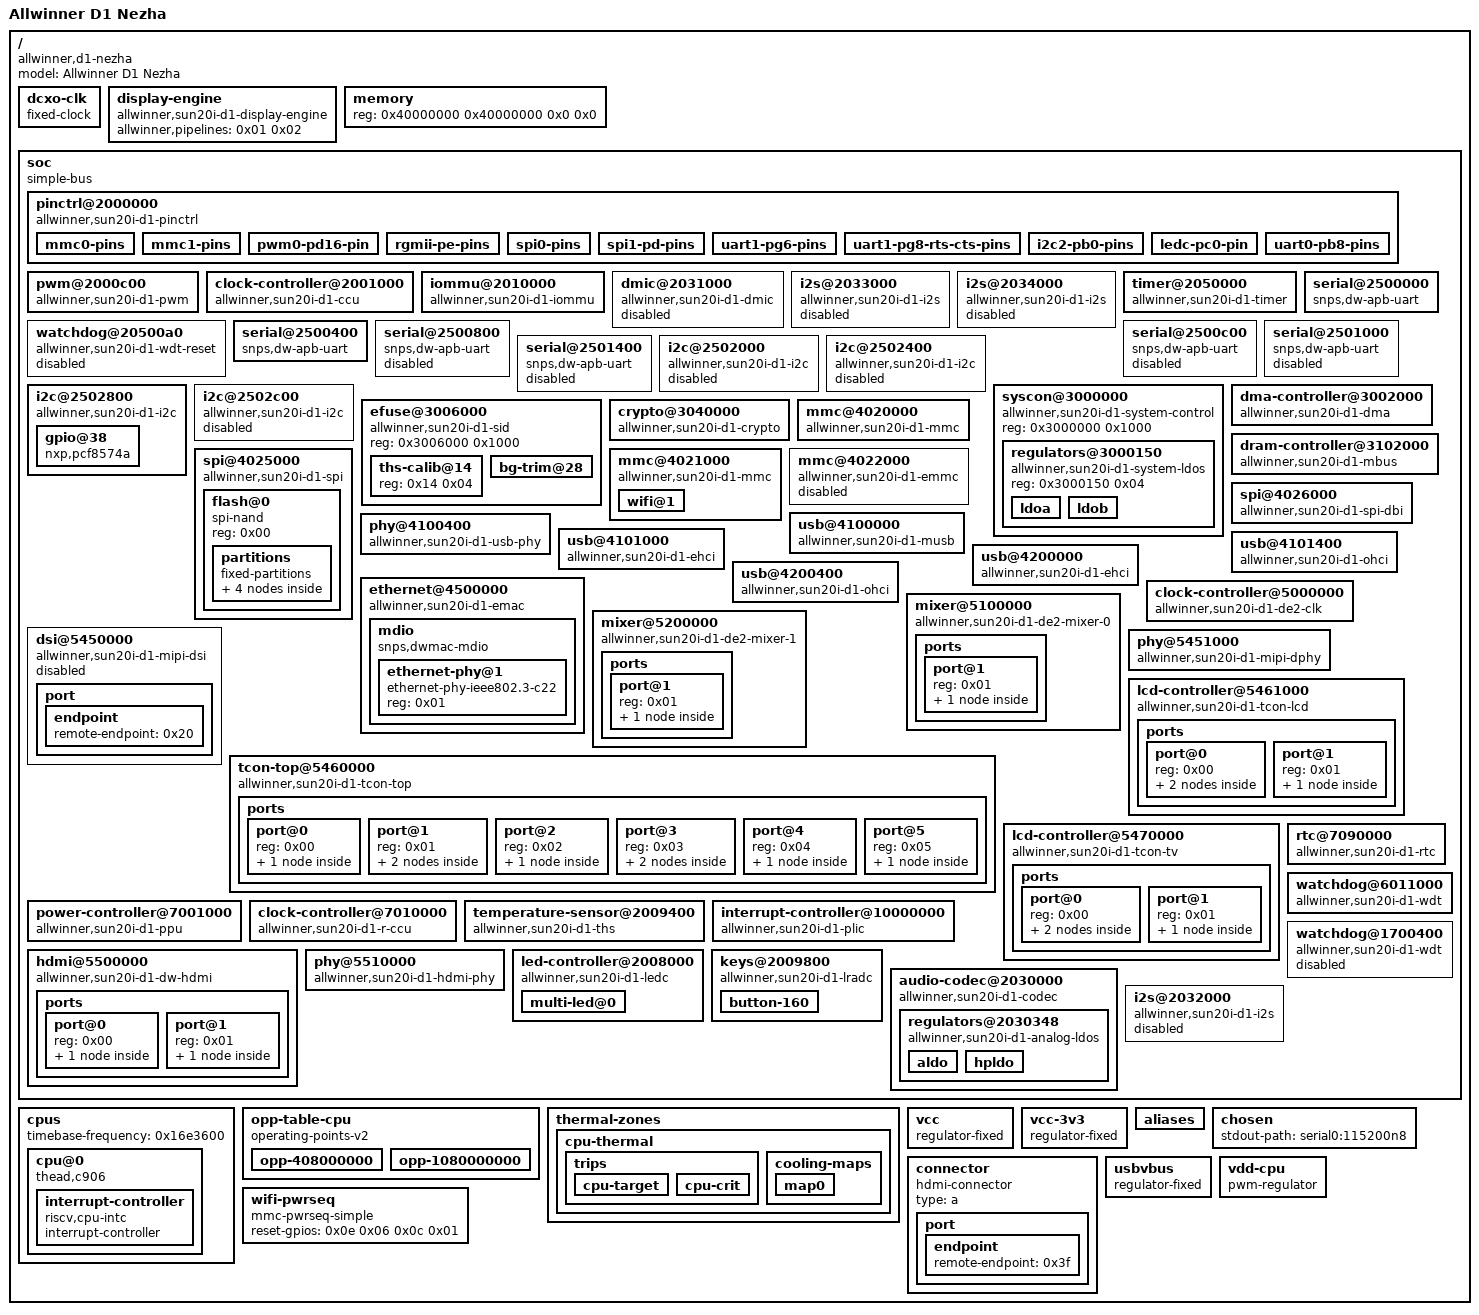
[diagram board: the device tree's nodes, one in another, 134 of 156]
/dts-v1/;

/ {
	#address-cells = <0x01>;
	#size-cells = <0x01>;
	model = "Allwinner D1 Nezha";
	compatible = "allwinner,d1-nezha\0allwinner,sun20i-d1";

	dcxo-clk {
		compatible = "fixed-clock";
		clock-output-names = "dcxo";
		#clock-cells = <0x00>;
		clock-frequency = <0x16e3600>;
		phandle = <0x05>;
	};

	display-engine {
		compatible = "allwinner,sun20i-d1-display-engine";
		allwinner,pipelines = <0x01 0x02>;
		status = "okay";
	};

        memory {
                device_type = "memory";
                reg = <0x40000000 0x40000000 0x0 0x0>;
        };


	soc {
		compatible = "simple-bus";
		ranges;
		dma-noncoherent;
		#address-cells = <0x01>;
		#size-cells = <0x01>;
		interrupt-parent = <0x03>;

		pinctrl@2000000 {
			compatible = "allwinner,sun20i-d1-pinctrl";
			reg = <0x2000000 0x800>;
			interrupts = <0x55 0x04 0x57 0x04 0x59 0x04 0x5b 0x04 0x5d 0x04 0x5f 0x04>;
			clocks = <0x04 0x18 0x05 0x06 0x00>;
			clock-names = "apb\0hosc\0losc";
			gpio-controller;
			interrupt-controller;
			#gpio-cells = <0x03>;
			#interrupt-cells = <0x03>;
			vcc-pb-supply = <0x07>;
			vcc-pc-supply = <0x07>;
			vcc-pd-supply = <0x07>;
			vcc-pe-supply = <0x07>;
			vcc-pf-supply = <0x07>;
			vcc-pg-supply = <0x07>;
			gpio-line-names = "\0\0\0\0\0\0\0\0\0\0\0\0\0\0\0\0\0\0\0\0\0\0\0\0\0\0\0\0\0\0\0\0pin5 [gpio2/twi2-sck]\0pin3 [gpio1/twi2-sda]\0\0pin38 [gpio24/i2s2-din]\0pin40 [gpio25/i2s2-dout]\0pin12 [gpio7/i2s-clk]\0pin35 [gpio22/i2s2-lrck]\0\0pin8 [gpio4/uart0-txd]\0pin10 [gpio5/uart0-rxd]\0\0\0pin15 [gpio9]\0\0\0\0\0\0\0\0\0\0\0\0\0\0\0\0\0\0\0\0\0\0pin31 [gpio21]\0\0\0\0\0\0\0\0\0\0\0\0\0\0\0\0\0\0\0\0\0\0\0\0\0\0\0\0\0\0\0\0\0\0\0\0\0\0\0\0\0pin24 [gpio16/spi1-ce0]\0pin23 [gpio15/spi1-clk]\0pin19 [gpio12/spi1-mosi]\0pin21 [gpio13/spi1-miso]\0pin27 [gpio18/spi1-hold]\0pin29 [gpio20/spi1-wp]\0\0\0\0\0\0\0pin7 [gpio3/pwm]";
			phandle = <0x0e>;

			mmc0-pins {
				pins = "PF0\0PF1\0PF2\0PF3\0PF4\0PF5";
				function = "mmc0";
				phandle = <0x0f>;
			};

			mmc1-pins {
				pins = "PG0\0PG1\0PG2\0PG3\0PG4\0PG5";
				function = "mmc1";
				phandle = <0x11>;
			};

			pwm0-pd16-pin {
				pins = "PD16";
				function = "pwm0";
				phandle = <0x08>;
			};

			rgmii-pe-pins {
				pins = "PE0\0PE1\0PE2\0PE3\0PE4\0PE5\0PE6\0PE7\0PE8\0PE9\0PE11\0PE12\0PE13\0PE14\0PE15";
				function = "emac";
				phandle = <0x18>;
			};

			spi0-pins {
				pins = "PC2\0PC3\0PC4\0PC5\0PC6\0PC7";
				function = "spi0";
				phandle = <0x12>;
			};

			spi1-pd-pins {
				pins = "PD10\0PD11\0PD12\0PD13\0PD14\0PD15";
				function = "spi1";
				phandle = <0x13>;
			};

			uart1-pg6-pins {
				pins = "PG6\0PG7";
				function = "uart1";
				phandle = <0x0b>;
			};

			uart1-pg8-rts-cts-pins {
				pins = "PG8\0PG9";
				function = "uart1";
				phandle = <0x0c>;
			};

			i2c2-pb0-pins {
				pins = "PB0\0PB1";
				function = "i2c2";
				phandle = <0x0d>;
			};

			ledc-pc0-pin {
				pins = "PC0";
				function = "ledc";
				phandle = <0x36>;
			};

			uart0-pb8-pins {
				pins = "PB8\0PB9";
				function = "uart0";
				phandle = <0x0a>;
			};
		};

		pwm@2000c00 {
			compatible = "allwinner,sun20i-d1-pwm";
			reg = <0x2000c00 0x400>;
			interrupts = <0x22 0x04>;
			clocks = <0x04 0x2d 0x05>;
			clock-names = "bus\0mod";
			resets = <0x04 0x0d>;
			status = "okay";
			#pwm-cells = <0x03>;
			pinctrl-0 = <0x08>;
			pinctrl-names = "default";
			phandle = <0x40>;
		};

		clock-controller@2001000 {
			compatible = "allwinner,sun20i-d1-ccu";
			reg = <0x2001000 0x1000>;
			clocks = <0x05 0x06 0x00 0x06 0x02>;
			clock-names = "hosc\0losc\0iosc";
			#clock-cells = <0x01>;
			#reset-cells = <0x01>;
			phandle = <0x04>;
		};

		iommu@2010000 {
			compatible = "allwinner,sun20i-d1-iommu";
			reg = <0x2010000 0x10000>;
			interrupts = <0x50 0x04>;
			clocks = <0x04 0x2e>;
			#iommu-cells = <0x01>;
			phandle = <0x1b>;
		};

		dmic@2031000 {
			compatible = "allwinner,sun20i-d1-dmic\0allwinner,sun50i-h6-dmic";
			reg = <0x2031000 0x400>;
			interrupts = <0x28 0x04>;
			clocks = <0x04 0x5d 0x04 0x5c>;
			clock-names = "bus\0mod";
			resets = <0x04 0x26>;
			dmas = <0x09 0x08>;
			dma-names = "rx";
			status = "disabled";
			#sound-dai-cells = <0x00>;
		};

		i2s@2033000 {
			compatible = "allwinner,sun20i-d1-i2s\0allwinner,sun50i-r329-i2s";
			reg = <0x2033000 0x1000>;
			interrupts = <0x2b 0x04>;
			clocks = <0x04 0x57 0x04 0x53>;
			clock-names = "apb\0mod";
			resets = <0x04 0x23>;
			dmas = <0x09 0x04 0x09 0x04>;
			dma-names = "rx\0tx";
			status = "disabled";
			#sound-dai-cells = <0x00>;
		};

		i2s@2034000 {
			compatible = "allwinner,sun20i-d1-i2s\0allwinner,sun50i-r329-i2s";
			reg = <0x2034000 0x1000>;
			interrupts = <0x2c 0x04>;
			clocks = <0x04 0x58 0x04 0x54>;
			clock-names = "apb\0mod";
			resets = <0x04 0x24>;
			dmas = <0x09 0x05 0x09 0x05>;
			dma-names = "rx\0tx";
			status = "disabled";
			#sound-dai-cells = <0x00>;
		};

		timer@2050000 {
			compatible = "allwinner,sun20i-d1-timer\0allwinner,sun8i-a23-timer";
			reg = <0x2050000 0xa0>;
			interrupts = <0x4b 0x04 0x4c 0x04>;
			clocks = <0x05>;
		};

		watchdog@20500a0 {
			compatible = "allwinner,sun20i-d1-wdt-reset\0allwinner,sun20i-d1-wdt";
			reg = <0x20500a0 0x20>;
			interrupts = <0x4f 0x04>;
			clocks = <0x05 0x06 0x00>;
			clock-names = "hosc\0losc";
			status = "reserved";
		};

		serial@2500000 {
			compatible = "snps,dw-apb-uart";
			reg = <0x2500000 0x400>;
			reg-io-width = <0x04>;
			reg-shift = <0x02>;
			interrupts = <0x12 0x04>;
			clocks = <0x04 0x3e>;
			clock-names = "apb";
			resets = <0x04 0x12>;
			dmas = <0x09 0x0e 0x09 0x0e>;
			dma-names = "rx\0tx";
			status = "okay";
			pinctrl-0 = <0x0a>;
			pinctrl-names = "default";
		};

		serial@2500400 {
			compatible = "snps,dw-apb-uart";
			reg = <0x2500400 0x400>;
			reg-io-width = <0x04>;
			reg-shift = <0x02>;
			interrupts = <0x13 0x04>;
			clocks = <0x04 0x3f>;
			clock-names = "apb";
			resets = <0x04 0x13>;
			dmas = <0x09 0x0f 0x09 0x0f>;
			dma-names = "rx\0tx";
			status = "okay";
			uart-has-rtscts;
			pinctrl-0 = <0x0b 0x0c>;
			pinctrl-names = "default";
		};

		serial@2500800 {
			compatible = "snps,dw-apb-uart";
			reg = <0x2500800 0x400>;
			reg-io-width = <0x04>;
			reg-shift = <0x02>;
			interrupts = <0x14 0x04>;
			clocks = <0x04 0x40>;
			resets = <0x04 0x14>;
			dmas = <0x09 0x10 0x09 0x10>;
			dma-names = "rx\0tx";
			status = "disabled";
		};

		serial@2500c00 {
			compatible = "snps,dw-apb-uart";
			reg = <0x2500c00 0x400>;
			reg-io-width = <0x04>;
			reg-shift = <0x02>;
			interrupts = <0x15 0x04>;
			clocks = <0x04 0x41>;
			resets = <0x04 0x15>;
			dmas = <0x09 0x11 0x09 0x11>;
			dma-names = "rx\0tx";
			status = "disabled";
		};

		serial@2501000 {
			compatible = "snps,dw-apb-uart";
			reg = <0x2501000 0x400>;
			reg-io-width = <0x04>;
			reg-shift = <0x02>;
			interrupts = <0x16 0x04>;
			clocks = <0x04 0x42>;
			resets = <0x04 0x16>;
			dmas = <0x09 0x12 0x09 0x12>;
			dma-names = "rx\0tx";
			status = "disabled";
		};

		serial@2501400 {
			compatible = "snps,dw-apb-uart";
			reg = <0x2501400 0x400>;
			reg-io-width = <0x04>;
			reg-shift = <0x02>;
			interrupts = <0x17 0x04>;
			clocks = <0x04 0x43>;
			resets = <0x04 0x17>;
			dmas = <0x09 0x13 0x09 0x13>;
			dma-names = "rx\0tx";
			status = "disabled";
		};

		i2c@2502000 {
			compatible = "allwinner,sun20i-d1-i2c\0allwinner,sun8i-v536-i2c\0allwinner,sun6i-a31-i2c";
			reg = <0x2502000 0x400>;
			interrupts = <0x19 0x04>;
			clocks = <0x04 0x44>;
			resets = <0x04 0x18>;
			dmas = <0x09 0x2b 0x09 0x2b>;
			dma-names = "rx\0tx";
			status = "disabled";
			#address-cells = <0x01>;
			#size-cells = <0x00>;
		};

		i2c@2502400 {
			compatible = "allwinner,sun20i-d1-i2c\0allwinner,sun8i-v536-i2c\0allwinner,sun6i-a31-i2c";
			reg = <0x2502400 0x400>;
			interrupts = <0x1a 0x04>;
			clocks = <0x04 0x45>;
			resets = <0x04 0x19>;
			dmas = <0x09 0x2c 0x09 0x2c>;
			dma-names = "rx\0tx";
			status = "disabled";
			#address-cells = <0x01>;
			#size-cells = <0x00>;
		};

		i2c@2502800 {
			compatible = "allwinner,sun20i-d1-i2c\0allwinner,sun8i-v536-i2c\0allwinner,sun6i-a31-i2c";
			reg = <0x2502800 0x400>;
			interrupts = <0x1b 0x04>;
			clocks = <0x04 0x46>;
			resets = <0x04 0x1a>;
			dmas = <0x09 0x2d 0x09 0x2d>;
			dma-names = "rx\0tx";
			status = "okay";
			#address-cells = <0x01>;
			#size-cells = <0x00>;
			pinctrl-0 = <0x0d>;
			pinctrl-names = "default";

			gpio@38 {
				compatible = "nxp,pcf8574a";
				reg = <0x38>;
				interrupt-parent = <0x0e>;
				interrupts = <0x01 0x02 0x08>;
				interrupt-controller;
				gpio-controller;
				#gpio-cells = <0x02>;
				#interrupt-cells = <0x02>;
				gpio-line-names = "pin13 [gpio8]\0pin16 [gpio10]\0pin18 [gpio11]\0pin26 [gpio17]\0pin22 [gpio14]\0pin28 [gpio19]\0pin37 [gpio23]\0pin11 [gpio6]";
			};
		};

		i2c@2502c00 {
			compatible = "allwinner,sun20i-d1-i2c\0allwinner,sun8i-v536-i2c\0allwinner,sun6i-a31-i2c";
			reg = <0x2502c00 0x400>;
			interrupts = <0x1c 0x04>;
			clocks = <0x04 0x47>;
			resets = <0x04 0x1b>;
			dmas = <0x09 0x2e 0x09 0x2e>;
			dma-names = "rx\0tx";
			status = "disabled";
			#address-cells = <0x01>;
			#size-cells = <0x00>;
		};

		syscon@3000000 {
			compatible = "allwinner,sun20i-d1-system-control";
			reg = <0x3000000 0x1000>;
			ranges;
			#address-cells = <0x01>;
			#size-cells = <0x01>;
			phandle = <0x17>;

			regulators@3000150 {
				compatible = "allwinner,sun20i-d1-system-ldos";
				reg = <0x3000150 0x04>;

				ldoa {
					regulator-always-on;
					regulator-min-microvolt = <0x1b7740>;
					regulator-max-microvolt = <0x1b7740>;
					ldo-in-supply = <0x07>;
					phandle = <0x33>;
				};

				ldob {
				};
			};
		};

		dma-controller@3002000 {
			compatible = "allwinner,sun20i-d1-dma";
			reg = <0x3002000 0x1000>;
			interrupts = <0x42 0x04>;
			clocks = <0x04 0x25 0x04 0x30>;
			clock-names = "bus\0mbus";
			resets = <0x04 0x06>;
			dma-channels = <0x10>;
			dma-requests = <0x30>;
			#dma-cells = <0x01>;
			phandle = <0x09>;
		};

		efuse@3006000 {
			compatible = "allwinner,sun20i-d1-sid";
			reg = <0x3006000 0x1000>;
			#address-cells = <0x01>;
			#size-cells = <0x01>;

			ths-calib@14 {
				reg = <0x14 0x04>;
				phandle = <0x30>;
			};

			bg-trim@28 {
				reg = <0x28 0x04>;
				bits = <0x10 0x08>;
				phandle = <0x39>;
			};
		};

		crypto@3040000 {
			compatible = "allwinner,sun20i-d1-crypto";
			reg = <0x3040000 0x800>;
			interrupts = <0x44 0x04>;
			clocks = <0x04 0x22 0x04 0x21 0x04 0x32 0x06 0x02>;
			clock-names = "bus\0mod\0ram\0trng";
			resets = <0x04 0x04>;
		};

		dram-controller@3102000 {
			compatible = "allwinner,sun20i-d1-mbus";
			reg = <0x3102000 0x1000 0x3103000 0x1000>;
			reg-names = "mbus\0dram";
			interrupts = <0x3b 0x04>;
			clocks = <0x04 0x1a 0x04 0x2f 0x04 0x37>;
			clock-names = "mbus\0dram\0bus";
			dma-ranges = <0x00 0x40000000 0x80000000>;
			#address-cells = <0x01>;
			#size-cells = <0x01>;
			#interconnect-cells = <0x01>;
		};

		mmc@4020000 {
			compatible = "allwinner,sun20i-d1-mmc";
			reg = <0x4020000 0x1000>;
			interrupts = <0x38 0x04>;
			clocks = <0x04 0x3b 0x04 0x38>;
			clock-names = "ahb\0mmc";
			resets = <0x04 0x0f>;
			reset-names = "ahb";
			cap-sd-highspeed;
			max-frequency = <0x8f0d180>;
			no-mmc;
			status = "okay";
			#address-cells = <0x01>;
			#size-cells = <0x00>;
			bus-width = <0x04>;
			cd-gpios = <0x0e 0x05 0x06 0x00>;
			disable-wp;
			vmmc-supply = <0x07>;
			vqmmc-supply = <0x07>;
			pinctrl-0 = <0x0f>;
			pinctrl-names = "default";
		};

		mmc@4021000 {
			compatible = "allwinner,sun20i-d1-mmc";
			reg = <0x4021000 0x1000>;
			interrupts = <0x39 0x04>;
			clocks = <0x04 0x3c 0x04 0x39>;
			clock-names = "ahb\0mmc";
			resets = <0x04 0x10>;
			reset-names = "ahb";
			cap-sd-highspeed;
			max-frequency = <0x8f0d180>;
			no-mmc;
			status = "okay";
			#address-cells = <0x01>;
			#size-cells = <0x00>;
			bus-width = <0x04>;
			mmc-pwrseq = <0x10>;
			non-removable;
			vmmc-supply = <0x07>;
			vqmmc-supply = <0x07>;
			pinctrl-0 = <0x11>;
			pinctrl-names = "default";

			wifi@1 {
				reg = <0x01>;
				interrupt-parent = <0x0e>;
				interrupts = <0x06 0x0a 0x08>;
				interrupt-names = "host-wake";
			};
		};

		mmc@4022000 {
			compatible = "allwinner,sun20i-d1-emmc\0allwinner,sun50i-a100-emmc";
			reg = <0x4022000 0x1000>;
			interrupts = <0x3a 0x04>;
			clocks = <0x04 0x3d 0x04 0x3a>;
			clock-names = "ahb\0mmc";
			resets = <0x04 0x11>;
			reset-names = "ahb";
			cap-mmc-highspeed;
			max-frequency = <0x8f0d180>;
			mmc-ddr-1_8v;
			mmc-ddr-3_3v;
			no-sd;
			no-sdio;
			status = "disabled";
			#address-cells = <0x01>;
			#size-cells = <0x00>;
		};

		spi@4025000 {
			compatible = "allwinner,sun20i-d1-spi\0allwinner,sun50i-r329-spi";
			reg = <0x4025000 0x1000>;
			interrupts = <0x1f 0x04>;
			clocks = <0x04 0x4a 0x04 0x48>;
			clock-names = "ahb\0mod";
			resets = <0x04 0x1c>;
			dmas = <0x09 0x16 0x09 0x16>;
			dma-names = "rx\0tx";
			num-cs = <0x01>;
			status = "okay";
			#address-cells = <0x01>;
			#size-cells = <0x00>;
			pinctrl-0 = <0x12>;
			pinctrl-names = "default";

			flash@0 {
				compatible = "spi-nand";
				reg = <0x00>;

				partitions {
					compatible = "fixed-partitions";
					#address-cells = <0x01>;
					#size-cells = <0x01>;

					partition@0 {
						label = "boot0";
						reg = <0x00 0x100000>;
					};

					partition@100000 {
						label = "uboot";
						reg = <0x100000 0x300000>;
					};

					partition@400000 {
						label = "secure_storage";
						reg = <0x400000 0x100000>;
					};

					partition@500000 {
						label = "sys";
						reg = <0x500000 0xfb00000>;
					};
				};
			};
		};

		spi@4026000 {
			compatible = "allwinner,sun20i-d1-spi-dbi\0allwinner,sun50i-r329-spi-dbi\0allwinner,sun50i-r329-spi";
			reg = <0x4026000 0x1000>;
			interrupts = <0x20 0x04>;
			clocks = <0x04 0x4b 0x04 0x49>;
			clock-names = "ahb\0mod";
			resets = <0x04 0x1d>;
			dmas = <0x09 0x17 0x09 0x17>;
			dma-names = "rx\0tx";
			num-cs = <0x01>;
			status = "okay";
			#address-cells = <0x01>;
			#size-cells = <0x00>;
			pinctrl-0 = <0x13>;
			pinctrl-names = "default";
		};

		usb@4100000 {
			compatible = "allwinner,sun20i-d1-musb\0allwinner,sun8i-a33-musb";
			reg = <0x4100000 0x400>;
			interrupts = <0x2d 0x04>;
			interrupt-names = "mc";
			clocks = <0x04 0x67>;
			resets = <0x04 0x2e>;
			extcon = <0x14 0x00>;
			phys = <0x14 0x00>;
			phy-names = "usb";
			status = "okay";
			dr_mode = "otg";
		};

		phy@4100400 {
			compatible = "allwinner,sun20i-d1-usb-phy";
			reg = <0x4100400 0x100 0x4101800 0x100 0x4200800 0x100>;
			reg-names = "phy_ctrl\0pmu0\0pmu1";
			clocks = <0x05 0x05>;
			clock-names = "usb0_phy\0usb1_phy";
			resets = <0x04 0x28 0x04 0x29>;
			reset-names = "usb0_reset\0usb1_reset";
			status = "okay";
			#phy-cells = <0x01>;
			usb0_id_det-gpios = <0x0e 0x03 0x15 0x00>;
			usb0_vbus_det-gpios = <0x0e 0x03 0x14 0x00>;
			usb0_vbus-supply = <0x15>;
			usb1_vbus-supply = <0x16>;
			phandle = <0x14>;
		};

		usb@4101000 {
			compatible = "allwinner,sun20i-d1-ehci\0generic-ehci";
			reg = <0x4101000 0x100>;
			interrupts = <0x2e 0x04>;
			clocks = <0x04 0x63 0x04 0x65 0x04 0x61>;
			resets = <0x04 0x2a 0x04 0x2c>;
			phys = <0x14 0x00>;
			phy-names = "usb";
			status = "okay";
		};

		usb@4101400 {
			compatible = "allwinner,sun20i-d1-ohci\0generic-ohci";
			reg = <0x4101400 0x100>;
			interrupts = <0x2f 0x04>;
			clocks = <0x04 0x63 0x04 0x61>;
			resets = <0x04 0x2a>;
			phys = <0x14 0x00>;
			phy-names = "usb";
			status = "okay";
		};

		usb@4200000 {
			compatible = "allwinner,sun20i-d1-ehci\0generic-ehci";
			reg = <0x4200000 0x100>;
			interrupts = <0x31 0x04>;
			clocks = <0x04 0x64 0x04 0x66 0x04 0x62>;
			resets = <0x04 0x2b 0x04 0x2d>;
			phys = <0x14 0x01>;
			phy-names = "usb";
			status = "okay";
		};

		usb@4200400 {
			compatible = "allwinner,sun20i-d1-ohci\0generic-ohci";
			reg = <0x4200400 0x100>;
			interrupts = <0x32 0x04>;
			clocks = <0x04 0x64 0x04 0x62>;
			resets = <0x04 0x2b>;
			phys = <0x14 0x01>;
			phy-names = "usb";
			status = "okay";
		};

		ethernet@4500000 {
			compatible = "allwinner,sun20i-d1-emac\0allwinner,sun50i-a64-emac";
			reg = <0x4500000 0x10000>;
			interrupts = <0x3e 0x04>;
			interrupt-names = "macirq";
			clocks = <0x04 0x4d>;
			clock-names = "stmmaceth";
			resets = <0x04 0x1e>;
			reset-names = "stmmaceth";
			syscon = <0x17>;
			status = "okay";
			pinctrl-0 = <0x18>;
			pinctrl-names = "default";
			phy-handle = <0x19>;
			phy-mode = "rgmii-id";
			phy-supply = <0x07>;

			mdio {
				compatible = "snps,dwmac-mdio";
				#address-cells = <0x01>;
				#size-cells = <0x00>;

				ethernet-phy@1 {
					compatible = "ethernet-phy-ieee802.3-c22";
					reg = <0x01>;
					phandle = <0x19>;
				};
			};
		};

		clock-controller@5000000 {
			compatible = "allwinner,sun20i-d1-de2-clk\0allwinner,sun50i-h5-de2-clk";
			reg = <0x5000000 0x10000>;
			clocks = <0x04 0x1c 0x04 0x1b>;
			clock-names = "bus\0mod";
			resets = <0x04 0x01>;
			#clock-cells = <0x01>;
			#reset-cells = <0x01>;
			phandle = <0x1a>;
		};

		mixer@5100000 {
			compatible = "allwinner,sun20i-d1-de2-mixer-0";
			reg = <0x5100000 0x100000>;
			clocks = <0x1a 0x00 0x1a 0x06>;
			clock-names = "bus\0mod";
			resets = <0x1a 0x00>;
			iommus = <0x1b 0x02>;
			phandle = <0x01>;

			ports {
				#address-cells = <0x01>;
				#size-cells = <0x00>;

				port@1 {
					reg = <0x01>;

					endpoint {
						remote-endpoint = <0x1c>;
						phandle = <0x21>;
					};
				};
			};
		};

		mixer@5200000 {
			compatible = "allwinner,sun20i-d1-de2-mixer-1";
			reg = <0x5200000 0x100000>;
			clocks = <0x1a 0x01 0x1a 0x07>;
			clock-names = "bus\0mod";
			resets = <0x1a 0x01>;
			iommus = <0x1b 0x02>;
			phandle = <0x02>;

			ports {
				#address-cells = <0x01>;
				#size-cells = <0x00>;

				port@1 {
					reg = <0x01>;

					endpoint {
						remote-endpoint = <0x1d>;
						phandle = <0x24>;
					};
				};
			};
		};

		dsi@5450000 {
			compatible = "allwinner,sun20i-d1-mipi-dsi\0allwinner,sun50i-a100-mipi-dsi";
			reg = <0x5450000 0x1000>;
			interrupts = <0x6c 0x04>;
			clocks = <0x04 0x6f 0x1e 0x02>;
			clock-names = "bus\0mod";
			resets = <0x04 0x33>;
			phys = <0x1f>;
			phy-names = "dphy";
			status = "disabled";

			port {

				endpoint {
					remote-endpoint = <0x20>;
					phandle = <0x2b>;
				};
			};
		};

		phy@5451000 {
			compatible = "allwinner,sun20i-d1-mipi-dphy\0allwinner,sun50i-a100-mipi-dphy";
			reg = <0x5451000 0x1000>;
			interrupts = <0x6c 0x04>;
			clocks = <0x04 0x6f 0x04 0x6e>;
			clock-names = "bus\0mod";
			resets = <0x04 0x33>;
			#phy-cells = <0x00>;
			phandle = <0x1f>;
		};

		tcon-top@5460000 {
			compatible = "allwinner,sun20i-d1-tcon-top";
			reg = <0x5460000 0x1000>;
			clocks = <0x04 0x69 0x04 0x72 0x04 0x74 0x04 0x70>;
			clock-names = "bus\0tcon-tv0\0tve0\0dsi";
			clock-output-names = "tcon-top-tv0\0tcon-top-dsi";
			resets = <0x04 0x30>;
			#clock-cells = <0x01>;
			phandle = <0x1e>;

			ports {
				#address-cells = <0x01>;
				#size-cells = <0x00>;

				port@0 {
					reg = <0x00>;

					endpoint {
						remote-endpoint = <0x21>;
						phandle = <0x1c>;
					};
				};

				port@1 {
					reg = <0x01>;
					#address-cells = <0x01>;
					#size-cells = <0x00>;

					endpoint@0 {
						reg = <0x00>;
						remote-endpoint = <0x22>;
						phandle = <0x29>;
					};

					endpoint@2 {
						reg = <0x02>;
						remote-endpoint = <0x23>;
						phandle = <0x2c>;
					};
				};

				port@2 {
					reg = <0x02>;
					#address-cells = <0x01>;
					#size-cells = <0x00>;

					endpoint@1 {
						reg = <0x01>;
						remote-endpoint = <0x24>;
						phandle = <0x1d>;
					};
				};

				port@3 {
					reg = <0x03>;
					#address-cells = <0x01>;
					#size-cells = <0x00>;

					endpoint@0 {
						reg = <0x00>;
						remote-endpoint = <0x25>;
						phandle = <0x2a>;
					};

					endpoint@2 {
						reg = <0x02>;
						remote-endpoint = <0x26>;
						phandle = <0x2d>;
					};
				};

				port@4 {
					reg = <0x04>;

					endpoint {
						remote-endpoint = <0x27>;
						phandle = <0x2e>;
					};
				};

				port@5 {
					reg = <0x05>;

					endpoint {
						remote-endpoint = <0x28>;
						phandle = <0x34>;
					};
				};
			};
		};

		lcd-controller@5461000 {
			compatible = "allwinner,sun20i-d1-tcon-lcd";
			reg = <0x5461000 0x1000>;
			interrupts = <0x6a 0x04>;
			clocks = <0x04 0x71 0x04 0x70>;
			clock-names = "ahb\0tcon-ch0";
			clock-output-names = "tcon-pixel-clock";
			resets = <0x04 0x34 0x04 0x36>;
			reset-names = "lcd\0lvds";
			phys = <0x1f>;
			phy-names = "lvds0";
			#clock-cells = <0x00>;

			ports {
				#address-cells = <0x01>;
				#size-cells = <0x00>;

				port@0 {
					reg = <0x00>;
					#address-cells = <0x01>;
					#size-cells = <0x00>;

					endpoint@0 {
						reg = <0x00>;
						remote-endpoint = <0x29>;
						phandle = <0x22>;
					};

					endpoint@1 {
						reg = <0x01>;
						remote-endpoint = <0x2a>;
						phandle = <0x25>;
					};
				};

				port@1 {
					reg = <0x01>;
					#address-cells = <0x01>;
					#size-cells = <0x00>;

					endpoint@1 {
						reg = <0x01>;
						remote-endpoint = <0x2b>;
						phandle = <0x20>;
					};
				};
			};
		};

		lcd-controller@5470000 {
			compatible = "allwinner,sun20i-d1-tcon-tv";
			reg = <0x5470000 0x1000>;
			interrupts = <0x6b 0x04>;
			clocks = <0x04 0x73 0x1e 0x00>;
			clock-names = "ahb\0tcon-ch1";
			resets = <0x04 0x35>;
			reset-names = "lcd";

			ports {
				#address-cells = <0x01>;
				#size-cells = <0x00>;

				port@0 {
					reg = <0x00>;
					#address-cells = <0x01>;
					#size-cells = <0x00>;

					endpoint@0 {
						reg = <0x00>;
						remote-endpoint = <0x2c>;
						phandle = <0x23>;
					};

					endpoint@1 {
						reg = <0x01>;
						remote-endpoint = <0x2d>;
						phandle = <0x26>;
					};
				};

				port@1 {
					reg = <0x01>;

					endpoint {
						remote-endpoint = <0x2e>;
						phandle = <0x27>;
					};
				};
			};
		};

		power-controller@7001000 {
			compatible = "allwinner,sun20i-d1-ppu";
			reg = <0x7001000 0x1000>;
			clocks = <0x2f 0x04>;
			resets = <0x2f 0x02>;
			#power-domain-cells = <0x01>;
		};

		clock-controller@7010000 {
			compatible = "allwinner,sun20i-d1-r-ccu";
			reg = <0x7010000 0x400>;
			clocks = <0x05 0x06 0x00 0x06 0x02 0x04 0x06>;
			clock-names = "hosc\0losc\0iosc\0pll-periph";
			#clock-cells = <0x01>;
			#reset-cells = <0x01>;
			phandle = <0x2f>;
		};

		rtc@7090000 {
			compatible = "allwinner,sun20i-d1-rtc\0allwinner,sun50i-r329-rtc";
			reg = <0x7090000 0x400>;
			interrupts = <0xa0 0x04>;
			clocks = <0x2f 0x07 0x05 0x2f 0x00>;
			clock-names = "bus\0hosc\0ahb";
			#clock-cells = <0x01>;
			phandle = <0x06>;
		};

		temperature-sensor@2009400 {
			compatible = "allwinner,sun20i-d1-ths";
			reg = <0x2009400 0x400>;
			interrupts = <0x4a 0x04>;
			clocks = <0x04 0x51 0x05>;
			clock-names = "bus\0mod";
			resets = <0x04 0x21>;
			nvmem-cells = <0x30>;
			nvmem-cell-names = "calibration";
			#thermal-sensor-cells = <0x00>;
			phandle = <0x3c>;
		};

		watchdog@6011000 {
			compatible = "allwinner,sun20i-d1-wdt";
			reg = <0x6011000 0x20>;
			interrupts = <0x93 0x04>;
			clocks = <0x05 0x06 0x00>;
			clock-names = "hosc\0losc";
		};

		interrupt-controller@10000000 {
			compatible = "allwinner,sun20i-d1-plic\0thead,c900-plic";
			reg = <0x10000000 0x4000000>;
			interrupts-extended = <0x31 0x0b 0x31 0x09>;
			interrupt-controller;
			riscv,ndev = <0xaf>;
			#address-cells = <0x00>;
			#interrupt-cells = <0x02>;
			phandle = <0x03>;
		};

		watchdog@1700400 {
			compatible = "allwinner,sun20i-d1-wdt";
			reg = <0x1700400 0x20>;
			interrupts = <0x8a 0x04>;
			clocks = <0x05 0x06 0x00>;
			clock-names = "hosc\0losc";
			status = "reserved";
		};

		hdmi@5500000 {
			compatible = "allwinner,sun20i-d1-dw-hdmi";
			reg = <0x5500000 0x10000>;
			reg-io-width = <0x01>;
			interrupts = <0x6d 0x04>;
			clocks = <0x04 0x6d 0x04 0x6a 0x04 0x6c>;
			clock-names = "iahb\0isfr\0cec";
			resets = <0x04 0x31>;
			reset-names = "ctrl";
			phys = <0x32>;
			phy-names = "phy";
			status = "okay";
			hvcc-supply = <0x33>;

			ports {
				#address-cells = <0x01>;
				#size-cells = <0x00>;

				port@0 {
					reg = <0x00>;

					endpoint {
						remote-endpoint = <0x34>;
						phandle = <0x28>;
					};
				};

				port@1 {
					reg = <0x01>;

					endpoint {
						remote-endpoint = <0x35>;
						phandle = <0x3f>;
					};
				};
			};
		};

		phy@5510000 {
			compatible = "allwinner,sun20i-d1-hdmi-phy";
			reg = <0x5510000 0x10000>;
			clocks = <0x04 0x6d 0x04 0x6a>;
			clock-names = "bus\0mod";
			resets = <0x04 0x32>;
			reset-names = "phy";
			status = "okay";
			#phy-cells = <0x00>;
			phandle = <0x32>;
		};

		led-controller@2008000 {
			compatible = "allwinner,sun20i-d1-ledc\0allwinner,sun50i-a100-ledc";
			reg = <0x2008000 0x400>;
			interrupts = <0x24 0x04>;
			clocks = <0x04 0x7b 0x04 0x7a>;
			clock-names = "bus\0mod";
			resets = <0x04 0x3b>;
			dmas = <0x09 0x2a>;
			dma-names = "tx";
			status = "okay";
			#address-cells = <0x01>;
			#size-cells = <0x00>;
			pinctrl-0 = <0x36>;
			pinctrl-names = "default";

			multi-led@0 {
				reg = <0x00>;
				color = <0x09>;
				function = "status";
			};
		};

		keys@2009800 {
			compatible = "allwinner,sun20i-d1-lradc\0allwinner,sun50i-r329-lradc";
			reg = <0x2009800 0x400>;
			interrupts = <0x4d 0x04>;
			clocks = <0x04 0x68>;
			resets = <0x04 0x2f>;
			vref-supply = <0x37>;
			status = "okay";

			button-160 {
				label = "OK";
				linux,code = <0x160>;
				channel = <0x00>;
				voltage = <0x27100>;
			};
		};

		audio-codec@2030000 {
			compatible = "allwinner,sun20i-d1-codec\0simple-mfd\0syscon";
			reg = <0x2030000 0x1000>;
			interrupts = <0x29 0x04>;
			clocks = <0x04 0x60 0x04 0x5f 0x04 0x5e 0x05 0x06 0x00>;
			clock-names = "bus\0adc\0dac\0hosc\0losc";
			resets = <0x04 0x27>;
			dmas = <0x09 0x07 0x09 0x07>;
			dma-names = "rx\0tx";
			avcc-supply = <0x37>;
			hpvcc-supply = <0x38>;
			#address-cells = <0x01>;
			#size-cells = <0x01>;
			#sound-dai-cells = <0x00>;
			routing = "Headphone Jack\0HPOUTL\0Headphone Jack\0HPOUTR\0LINEINL\0HPOUTL\0LINEINR\0HPOUTR\0MICIN3\0Headset Microphone\0Headset Microphone\0HBIAS";
			widgets = "Microphone\0Headset Microphone\0Headphone\0Headphone Jack";
			status = "okay";

			regulators@2030348 {
				compatible = "allwinner,sun20i-d1-analog-ldos";
				reg = <0x2030348 0x04>;
				nvmem-cells = <0x39>;
				nvmem-cell-names = "bg_trim";

				aldo {
					regulator-min-microvolt = <0x1b7740>;
					regulator-max-microvolt = <0x1b7740>;
					regulator-always-on;
					vdd33-supply = <0x07>;
					phandle = <0x37>;
				};

				hpldo {
					regulator-min-microvolt = <0x1b7740>;
					regulator-max-microvolt = <0x1b7740>;
					hpldoin-supply = <0x07>;
					phandle = <0x38>;
				};
			};
		};

		i2s@2032000 {
			compatible = "allwinner,sun20i-d1-i2s\0allwinner,sun50i-r329-i2s";
			reg = <0x2032000 0x1000>;
			interrupts = <0x2a 0x04>;
			clocks = <0x04 0x56 0x04 0x52>;
			clock-names = "apb\0mod";
			resets = <0x04 0x22>;
			dmas = <0x09 0x03 0x09 0x03>;
			dma-names = "rx\0tx";
			status = "disabled";
			#sound-dai-cells = <0x00>;
		};
	};

	cpus {
		timebase-frequency = <0x16e3600>;
		#address-cells = <0x01>;
		#size-cells = <0x00>;

		cpu@0 {
			compatible = "thead,c906\0riscv";
			device_type = "cpu";
			reg = <0x00>;
			clocks = <0x04 0x84>;
			d-cache-block-size = <0x40>;
			d-cache-sets = <0x100>;
			d-cache-size = <0x8000>;
			i-cache-block-size = <0x40>;
			i-cache-sets = <0x80>;
			i-cache-size = <0x8000>;
			mmu-type = "riscv,sv39";
			operating-points-v2 = <0x3a>;
			riscv,isa = "rv64imafdc";
			#cooling-cells = <0x02>;
			cpu-supply = <0x3b>;
			phandle = <0x3e>;

			interrupt-controller {
				compatible = "riscv,cpu-intc";
				interrupt-controller;
				#address-cells = <0x00>;
				#interrupt-cells = <0x01>;
				phandle = <0x31>;
			};
		};
	};

	opp-table-cpu {
		compatible = "operating-points-v2";
		phandle = <0x3a>;

		opp-408000000 {
			opp-hz = <0x00 0x18519600>;
			opp-microvolt = <0xdbba0 0xdbba0 0x10c8e0>;
		};

		opp-1080000000 {
			opp-hz = <0x00 0x3c14dc00>;
			opp-microvolt = <0xdbba0 0xdbba0 0x10c8e0>;
		};
	};

	thermal-zones {

		cpu-thermal {
			polling-delay = <0x00>;
			polling-delay-passive = <0x00>;
			thermal-sensors = <0x3c>;

			trips {

				cpu-target {
					hysteresis = <0xbb8>;
					temperature = <0x14c08>;
					type = "passive";
					phandle = <0x3d>;
				};

				cpu-crit {
					hysteresis = <0x00>;
					temperature = <0x1adb0>;
					type = "critical";
				};
			};

			cooling-maps {

				map0 {
					trip = <0x3d>;
					cooling-device = <0x3e 0xffffffff 0xffffffff>;
				};
			};
		};
	};

	vcc {
		compatible = "regulator-fixed";
		regulator-name = "vcc";
		regulator-min-microvolt = <0x4c4b40>;
		regulator-max-microvolt = <0x4c4b40>;
		phandle = <0x16>;
	};

	vcc-3v3 {
		compatible = "regulator-fixed";
		regulator-name = "vcc-3v3";
		regulator-min-microvolt = <0x325aa0>;
		regulator-max-microvolt = <0x325aa0>;
		vin-supply = <0x16>;
		phandle = <0x07>;
	};

	aliases {
		ethernet0 = "/soc/ethernet@4500000";
		ethernet1 = "/soc/mmc@4021000/wifi@1";
		serial0 = "/soc/serial@2500000";
		spi0 = "/soc/spi@4025000";
	};

	chosen {
		stdout-path = "serial0:115200n8";
	};

	connector {
		compatible = "hdmi-connector";
		type = "a";

		port {

			endpoint {
				remote-endpoint = <0x3f>;
				phandle = <0x35>;
			};
		};
	};

	usbvbus {
		compatible = "regulator-fixed";
		regulator-name = "usbvbus";
		regulator-min-microvolt = <0x4c4b40>;
		regulator-max-microvolt = <0x4c4b40>;
		gpio = <0x0e 0x03 0x13 0x00>;
		enable-active-high;
		vin-supply = <0x16>;
		phandle = <0x15>;
	};

	vdd-cpu {
		compatible = "pwm-regulator";
		pwms = <0x40 0x00 0xc350 0x00>;
		pwm-supply = <0x16>;
		regulator-name = "vdd-cpu";
		regulator-min-microvolt = <0xc5c10>;
		regulator-max-microvolt = <0x11b340>;
		phandle = <0x3b>;
	};

	wifi-pwrseq {
		compatible = "mmc-pwrseq-simple";
		reset-gpios = <0x0e 0x06 0x0c 0x01>;
		phandle = <0x10>;
	};
};
